# ESP32 register map
Vendor: ESPRESSIF SYSTEMS (SHANGHAI) CO., LTD.; Series: ESP32 Series; File version: 17
CPU: Xtensa LX6 r0p0, little endian, no MPU, FPU, 0 interrupt priority bits
Address unit: 32 bits
Registers are 32-bit, read-write, reset 0x0 unless marked. A register's access mark holds for its fields unless they carry their own. Offsets are from the block's base; [hi:lo] are bit positions; {n}, {i} and the like mark numbered series.

## RNG — Hardware Random Number Generator
Base 0x60035000
0x144 DATA ro — Random number data

## RSA — RSA (Rivest Shamir Adleman) Accelerator
Base 0x3FF02000
{0x0+4i} M_MEM[{i}] (i=0..127) — Represents M
{0x200+4i} Z_MEM[{i}] (i=0..127) — Represents Z
{0x400+4i} Y_MEM[{i}] (i=0..127) — Represents Y
{0x600+4i} X_MEM[{i}] (i=0..127) — Represents X
0x800 M_PRIME
  [7:0] M_PRIME — This register contains M’.
0x804 MODEXP_MODE
  [2:0] MODEXP_MODE — This register contains the mode of modular exponentiation.
0x808 MODEXP_START wo
  [0] MODEXP_START — Write 1 to start modular exponentiation.
0x80C MULT_MODE
  [3:0] MULT_MODE — This register contains the mode of modular multiplication and multiplication.
0x810 MULT_START wo
  [0] MULT_START — Write 1 to start modular multiplication or multiplication.
0x814 INTERRUPT
  [0] INTERRUPT — RSA interrupt status register. Will read 1 once an operation has completed.
0x818 CLEAN ro
  [0] CLEAN — This bit will read 1 once the memory initialization is completed.

## RTC_I2C — Low-power I2C (Inter-Integrated Circuit) Controller
Base 0x3FF48C00
0x00 SCL_LOW_PERIOD
  [24:0] SCL_LOW_PERIOD — number of cycles that scl == 0
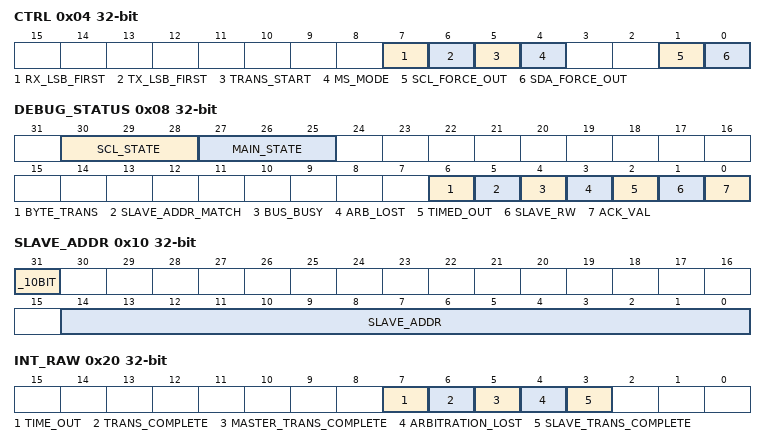
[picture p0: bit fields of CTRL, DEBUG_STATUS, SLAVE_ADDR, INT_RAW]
0x04 CTRL
  [7] RX_LSB_FIRST — Receive LSB first
  [6] TX_LSB_FIRST — Send LSB first
  [5] TRANS_START — Force to generate start condition
  [4] MS_MODE — Master (1) or slave (0)
  [1] SCL_FORCE_OUT — SCL is push-pull (1) or open-drain (0)
  [0] SDA_FORCE_OUT — SDA is push-pull (1) or open-drain (0)
0x08 DEBUG_STATUS
  [30:28] SCL_STATE — state of SCL state machine
  [27:25] MAIN_STATE — state of the main state machine
  [6] BYTE_TRANS — 8 bit transmit done
  [5] SLAVE_ADDR_MATCH — When working as a slave, whether address was matched
  [4] BUS_BUSY — operation is in progress
  [3] ARB_LOST — When working as a master, lost control of I2C bus
  [2] TIMED_OUT — Transfer has timed out
  [1] SLAVE_RW — When working as a slave, the value of R/W bit received
  [0] ACK_VAL — The value of an acknowledge signal on the bus
0x0C TIMEOUT
  [19:0] TIMEOUT — Maximum number of FAST_CLK cycles that the transmission can take
0x10 SLAVE_ADDR
  [31] _10BIT — Set if local slave address is 10-bit
  [14:0] SLAVE_ADDR — local slave address
0x1C DATA access not given
0x20 INT_RAW access per field
  [7] TIME_OUT ro — time out interrupt raw status
  [6] TRANS_COMPLETE rw — Stop condition has been detected interrupt raw status
  [5] MASTER_TRANS_COMPLETE rw
  [4] ARBITRATION_LOST rw — Master lost arbitration
  [3] SLAVE_TRANS_COMPLETE rw — Slave accepted 1 byte and address matched
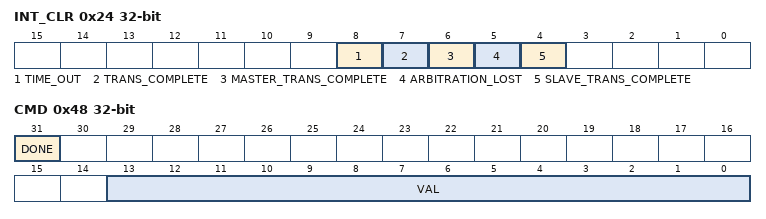
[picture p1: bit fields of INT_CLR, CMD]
0x24 INT_CLR access per field
  [8] TIME_OUT wo write-1-clears, [7] TRANS_COMPLETE rw write-1-clears, [6] MASTER_TRANS_COMPLETE rw write-1-clears, [5] ARBITRATION_LOST rw write-1-clears, [4] SLAVE_TRANS_COMPLETE rw write-1-clears
0x28 INT_ENA access not given
0x2C INT_ST access not given
0x30 SDA_DUTY
  [19:0] SDA_DUTY — Number of FAST_CLK cycles SDA will switch after falling edge of SCL
0x38 SCL_HIGH_PERIOD
  [19:0] SCL_HIGH_PERIOD — Number of FAST_CLK cycles for SCL to be high
0x40 SCL_START_PERIOD
  [19:0] SCL_START_PERIOD — Number of FAST_CLK cycles to wait before generating start condition
0x44 SCL_STOP_PERIOD
  [19:0] SCL_STOP_PERIOD — Number of FAST_CLK cycles to wait before generating stop condition
0x48 CMD
  [31] DONE — Bit is set by HW when command is done
  [13:0] VAL — Command content

## SHA — SHA (Secure Hash Algorithm) Accelerator
Base 0x3FF03000
{0x0+4i} TEXT{i} (i=0..31)
  [31:0] TEXT — SHA Message block and hash result register.
0x80 SHA1_START wo
  [0] SHA1_START — Write 1 to start an SHA-1 operation on the first message block.
0x84 SHA1_CONTINUE wo
  [0] SHA1_CONTINUE — Write 1 to continue the SHA-1 operation with subsequent blocks.
0x88 SHA1_LOAD wo
  [0] SHA1_LOAD — Write 1 to finish the SHA-1 operation to calculate the final message hash.
0x8C SHA1_BUSY ro
  [0] SHA1_BUSY — SHA-1 operation status: 1 if the SHA accelerator is processing data, 0 if it is idle.
0x90 SHA256_START wo
  [0] SHA256_START — Write 1 to start an SHA-256 operation on the first message block.
0x94 SHA256_CONTINUE wo
  [0] SHA256_CONTINUE — Write 1 to continue the SHA-256 operation with subsequent blocks.
0x98 SHA256_LOAD wo
  [0] SHA256_LOAD — Write 1 to finish the SHA-256 operation to calculate the final message hash.
0x9C SHA256_BUSY ro
  [0] SHA256_BUSY — SHA-256 operation status: 1 if the SHA accelerator is processing data, 0 if it is idle.
0xA0 SHA384_START wo
  [0] SHA384_START — Write 1 to start an SHA-384 operation on the first message block.
0xA4 SHA384_CONTINUE wo
  [0] SHA384_CONTINUE — Write 1 to continue the SHA-384 operation with subsequent blocks.
0xA8 SHA384_LOAD wo
  [0] SHA384_LOAD — Write 1 to finish the SHA-384 operation to calculate the final message hash.
0xAC SHA384_BUSY ro
  [0] SHA384_BUSY — SHA-384 operation status: 1 if the SHA accelerator is processing data, 0 if it is idle.
0xB0 SHA512_START wo
  [0] SHA512_START — Write 1 to start an SHA-512 operation on the first message block.
0xB4 SHA512_CONTINUE wo
  [0] SHA512_CONTINUE — Write 1 to continue the SHA-512 operation with subsequent blocks.
0xB8 SHA512_LOAD wo
  [0] SHA512_LOAD — Write 1 to finish the SHA-512 operation to calculate the final message hash.
0xBC SHA512_BUSY ro
  [0] SHA512_BUSY — SHA-512 operation status: 1 if the SHA accelerator is processing data, 0 if it is idle.

## MMU_TABLE — PRO CPU flash cache MMU table
Base 0x3FF10000
Same registers: APP_MMU_TABLE 0x3FF12000
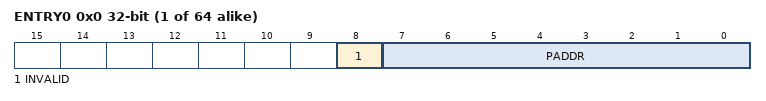
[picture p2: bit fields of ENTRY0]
{0x0+4i} ENTRY{i} (i=0..63) — Flash MMU table entry
  [8] INVALID — Set to mark this entry invalid
  [7:0] PADDR — Physical page number
